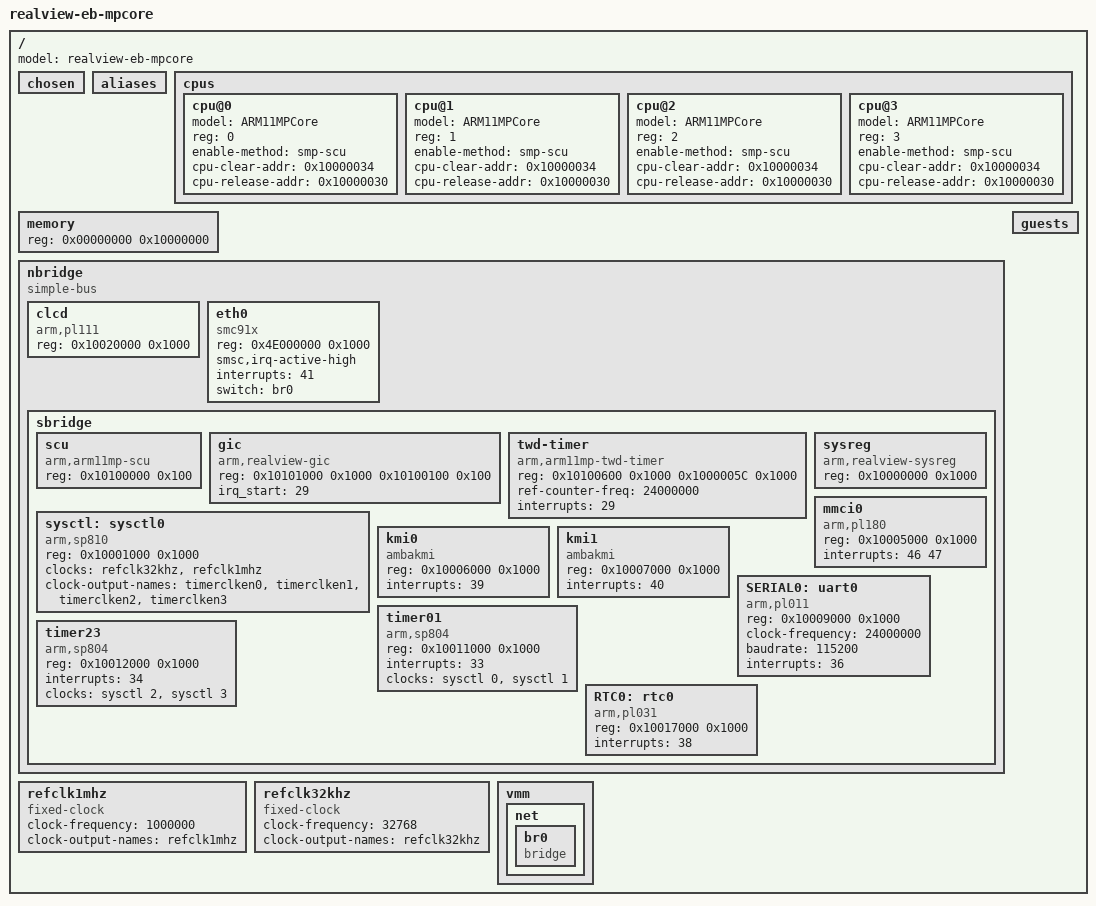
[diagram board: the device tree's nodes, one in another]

/ {
	#address-cells = <1>;
	#size-cells = <1>;
	model = "realview-eb-mpcore";

	chosen { };
	aliases { };

	cpus {
		#address-cells = <1>;
		#size-cells = <0>;

		cpu@0 {
			device_type = "cpu";
			model = "ARM11MPCore";
			reg = <0>;
			enable-method = "smp-scu";
			cpu-clear-addr = <0x10000034>;
			cpu-release-addr = <0x10000030>;
		};

		cpu@1 {
			device_type = "cpu";
			model = "ARM11MPCore";
			reg = <1>;
			enable-method = "smp-scu";
			cpu-clear-addr = <0x10000034>;
			cpu-release-addr = <0x10000030>;
		};

		cpu@2 {
			device_type = "cpu";
			model = "ARM11MPCore";
			reg = <2>;
			enable-method = "smp-scu";
			cpu-clear-addr = <0x10000034>;
			cpu-release-addr = <0x10000030>;
		};

		cpu@3 {
			device_type = "cpu";
			model = "ARM11MPCore";
			reg = <3>;
			enable-method = "smp-scu";
			cpu-clear-addr = <0x10000034>;
			cpu-release-addr = <0x10000030>;
		};
	};

	memory {
		device_type = "memory"; 
		reg = <0x00000000 0x10000000>; /* 256 MB */
	};

	nbridge {
		#address-cells = <1>;
		#size-cells = <1>;
		compatible = "simple-bus";

		clcd {
	      		device_type = "fb";
	      		compatible = "arm,pl111";
	      		reg = <0x10020000 0x1000>;
		};

		eth0 {
			device_type = "nic";
			compatible = "smc91x";
			reg = <0x4E000000 0x1000>;
			smsc,irq-active-high;
			interrupts = <41>;
			switch = "br0";
		};

		sbridge {
			#address-cells = <1>;
			#size-cells = <1>;

			scu { /* Snoop Control Unit */
		      		device_type = "scu";
				compatible = "arm,arm11mp-scu";
				reg = <0x10100000 0x100>;
			};

			gic { /* Generic Interrupt Controller */
		      		device_type = "pic";
		      		compatible = "arm,realview-gic";
		      		reg = <0x10101000 0x1000
				       0x10100100 0x100>;
				irq_start = <29>;
			};

			twd-timer { /* Local Timer */
		      		device_type = "timer";
		      		compatible = "arm,arm11mp-twd-timer";
		      		reg = <0x10100600 0x1000	/* Local timer registers */
				       0x1000005C 0x1000>;	/* Reference counter address */
				ref-counter-freq = <24000000>;	/* Reference counter frequency */
				interrupts = <29>;
			};

			sysreg { /* System Registers */
		      		device_type = "sys";
		      		compatible = "arm,realview-sysreg";
		      		reg = <0x10000000 0x1000>;
			};

			sysctl: sysctl0 { /* System Controller */
		      		device_type = "sys";
		      		compatible = "arm,sp810";
		      		reg = <0x10001000 0x1000>;
				clocks = <&refclk32khz>, <&refclk1mhz>;
				clock-names = "refclk", "timclk", "apb_pclk";
				#clock-cells = <1>;
				clock-output-names = "timerclken0", "timerclken1", "timerclken2", "timerclken3";
			};

			mmci0 { /* Multimedia Card Interface */
		      		device_type = "mmc";
		      		compatible = "arm,pl180";
		      		reg = <0x10005000 0x1000>;
				interrupts = <46 47>;
			};

			kmi0 { /* Keyboard */
		      		device_type = "serio";
		      		compatible = "ambakmi";
		      		reg = <0x10006000 0x1000>;
				interrupts = <39>;
			};

			kmi1 { /* Mouse */
		      		device_type = "serio";
		      		compatible = "ambakmi";
		      		reg = <0x10007000 0x1000>;
				interrupts = <40>;
			};

			SERIAL0: uart0 {
		      		device_type = "serial";
		      		compatible = "arm,pl011";
		      		reg = <0x10009000 0x1000>;
				clock-frequency = <24000000>;
		      		baudrate = <115200>;
				interrupts = <36>;
			};

			timer01 {
		      		device_type = "timer";
		      		compatible = "arm,sp804";
		      		reg = <0x10011000 0x1000>;
				interrupts = <33>;
				clocks = <&sysctl 0>, <&sysctl 1>;
				clock-names = "timclken1", "timclken2";
			};

			timer23 {
		      		device_type = "timer";
		      		compatible = "arm,sp804";
		      		reg = <0x10012000 0x1000>;
				interrupts = <34>;
				clocks = <&sysctl 2>, <&sysctl 3>;
				clock-names = "timclken1", "timclken2";
			};

			RTC0: rtc0 {
		      		device_type = "rtc";
		      		compatible = "arm,pl031";
		      		reg = <0x10017000 0x1000>;
				interrupts = <38>;
			};
		};
	};

	refclk1mhz: refclk1mhz {
		compatible = "fixed-clock";
		#clock-cells = <0>;
		clock-frequency = <1000000>;
		clock-output-names = "refclk1mhz";
	};

	refclk32khz: refclk32khz {
		compatible = "fixed-clock";
		#clock-cells = <0>;
		clock-frequency = <32768>;
		clock-output-names = "refclk32khz";
	};

	vmm {
		net {
			br0 {
				device_type = "netswitch";
				compatible = "bridge";
			};
		};
	};

	/* Empty guests node */
	guests {
	};
};

/* Add guest templates */
/include/ "../../../common/guests/realview-eb-mpcore.dtsi"

